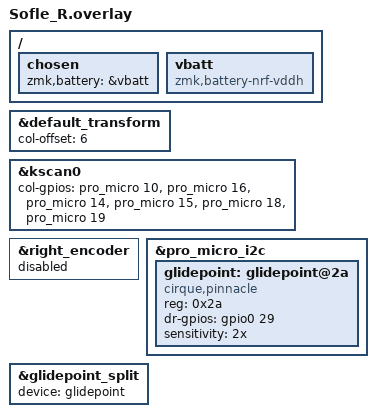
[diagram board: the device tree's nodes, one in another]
/*
 * Copyright (c) 2020 Ryan Cross
 *
 * SPDX-License-Identifier: MIT
 */

#include "Sofle.dtsi"

&default_transform {
    col-offset = <6>;
};
&kscan0 {
    col-gpios
        = <&pro_micro 10 GPIO_ACTIVE_HIGH>
        , <&pro_micro 16 GPIO_ACTIVE_HIGH>
        , <&pro_micro 14 GPIO_ACTIVE_HIGH>
        , <&pro_micro 15 GPIO_ACTIVE_HIGH>
        , <&pro_micro 18 GPIO_ACTIVE_HIGH>
        , <&pro_micro 19 GPIO_ACTIVE_HIGH>
        ;
};

/* Right encoder is not installed; its P0.29 pad is used for Cirque DR. */
&right_encoder {
    status = "disabled";
};

&pro_micro_i2c {
    glidepoint: glidepoint@2a {
        compatible = "cirque,pinnacle";
        reg = <0x2a>;
        status = "okay";
        dr-gpios = <&gpio0 29 GPIO_ACTIVE_HIGH>;
        sensitivity = "2x";
    };
};

&glidepoint_split {
    device = <&glidepoint>;
};
/ {
    chosen {
      zmk,battery = &vbatt;
    };

    vbatt: vbatt {
        compatible = "zmk,battery-nrf-vddh";
    };
};
